# XMC4800 register map
Vendor: Infineon; File version: 1.3.0 (Reference Manual v1.3)
CPU: CM4 r2p0, little endian, MPU, FPU, 6 interrupt priority bits
Registers are 32-bit, read-write, reset 0x0 unless marked. A register's access mark holds for its fields unless they carry their own. Offsets are from the block's base; [hi:lo] are bit positions; {n}, {i} and the like mark numbered series.

## USIC0 — Universal Serial Interface Controller 0
Base 0x40030008
Same registers: USIC1 0x48020008, USIC2 0x48024008
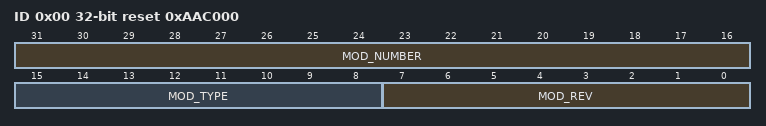
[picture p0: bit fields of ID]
0x00 ID ro reset 0xAAC000 (reset mask 0xFFFFFF00) — Module Identification Register
  [31:16] MOD_NUMBER — Module Number Value
  [15:8] MOD_TYPE — Module Type
  [7:0] MOD_REV — Module Revision Number

## CAN — Controller Area Networks
Base 0x48014000
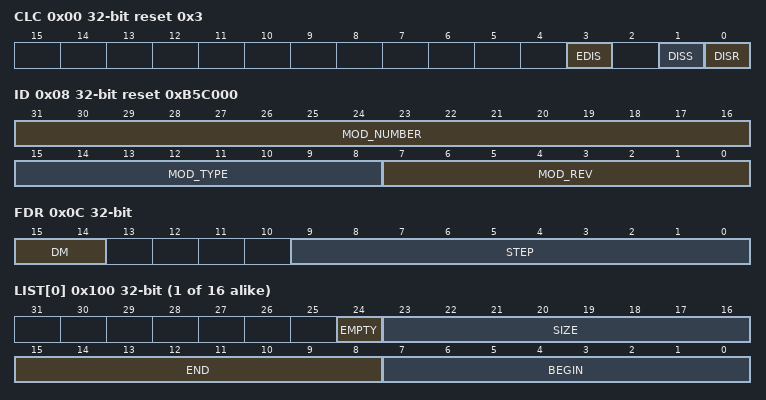
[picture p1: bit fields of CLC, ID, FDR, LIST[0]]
0x00 CLC access per field reset 0x3 — CAN Clock Control Register
  [3] EDIS rw — Sleep Mode Enable Control
  [1] DISS ro — Module Disable Status Bit
  [0] DISR rw — Module Disable Request Bit
0x08 ID ro reset 0xB5C000 (reset mask 0xFFFFFF00) — Module Identification Register
  [31:16] MOD_NUMBER — Module Number Value
  [15:8] MOD_TYPE — Module Type
    192=Define the module as a 32-bit module
  [7:0] MOD_REV — Module Revision Number
0x0C FDR — CAN Fractional Divider Register
  [15:14] DM — Divider Mode
  [9:0] STEP — Step Value
{0x100+4i} LIST[{i}] (i=0..15) ro reset not defined
  [24] EMPTY — List Empty Indication
    0=At least one message object is allocated to list i; 1=No message object is allocated to the list i. List i is empty.
  [23:16] SIZE — List Size
  [15:8] END — List End
  [7:0] BEGIN — List Begin
{0x140+4i} MSPND[{i}] (i=0..7) — Message Pending Register
  [31:0] PND — Message Pending
{0x180+4i} MSID[{i}] (i=0..7) ro reset 0x20 — Message Index Register
  [5:0] INDEX — Message Pending Index
0x1C0 MSIMASK — Message Index Mask Register
  [31:0] IM — Message Index Mask
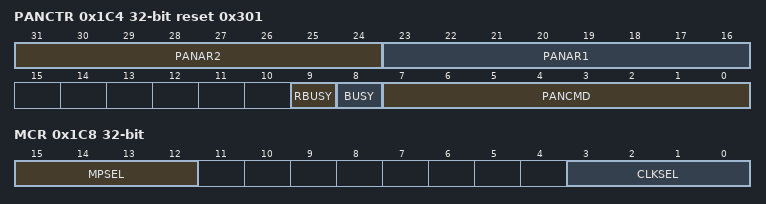
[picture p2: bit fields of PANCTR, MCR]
0x1C4 PANCTR access per field reset 0x301 — Panel Control Register
  [31:24] PANAR2 rw — Panel Argument 2
  [23:16] PANAR1 rw — Panel Argument 1
  [9] RBUSY ro — Result Busy Flag
    0=No update of PANAR1 and PANAR2 is scheduled by the list controller; 1=A list command is running (BUSY = 1) that will write results to PANAR1 and PANAR2, but the results are not yet available
  [8] BUSY ro — Panel Busy Flag
    0=Panel has finished command and is ready to accept a new command; 1=Panel operation is in progress
  [7:0] PANCMD rw — Panel Command
0x1C8 MCR — Module Control Register
  [15:12] MPSEL — Message Pending Selector
  [3:0] CLKSEL — Baud Rate Logic Clock Select
    0=No clock supplied; 1=fPERIPH; 2=fOHP; 4=hard wired to 0; 8=hard wired to 0
0x1CC MITR wo — Module Interrupt Trigger Register
  [7:0] IT — Interrupt Trigger

## DSD — Delta Sigma Demodulator
Base 0x40008000
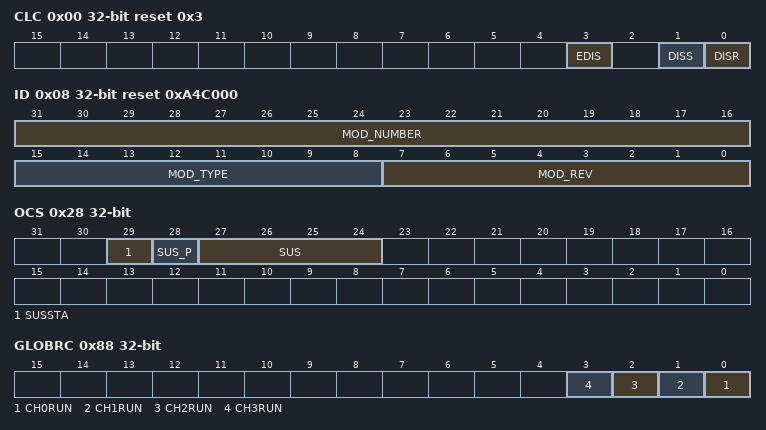
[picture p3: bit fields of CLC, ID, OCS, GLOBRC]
0x00 CLC access per field reset 0x3 — Clock Control Register
  [3] EDIS rw — Sleep Mode Enable Control
    0=Sleep mode request is enabled and functional; 1=Module disregards the sleep mode control signal
  [1] DISS ro — Module Disable Status Bit
    0=Module clock is enabled; 1=Off: module is not clocked
  [0] DISR rw — Module Disable Request Bit
    0=On request: enable the module clock; 1=Off request: stop the module clock
0x08 ID ro reset 0xA4C000 (reset mask 0xFFFFFF00) — Module Identification Register
  [31:16] MOD_NUMBER — Module Number
  [15:8] MOD_TYPE — Module Type
  [7:0] MOD_REV — Module Revision
0x28 OCS access per field — OCDS Control and Status Register
  [29] SUSSTA ro — Suspend State
    0=Module is not (yet) suspended; 1=Module is suspended
  [28] SUS_P wo — SUS Write Protection
  [27:24] SUS rw — OCDS Suspend Control
    0=Will not suspend; 1=Hard suspend: Clock is switched off immediately; 2=Soft suspend channel 0; 3=Soft suspend channel 1; 5=Soft suspend channel 3
0x80 GLOBCFG — Global Configuration Register
  [2:0] MCSEL — Modulator Clock Select
    0=Internal clock off, no source selected; 1=fDSD
0x88 GLOBRC — Global Run Control Register
  [all] fields
    0=Stop channel x; 1=Demodulator channel x is enabled and runs
  [n] CH{n}RUN (n=0..3) — Channel {n} Run Control
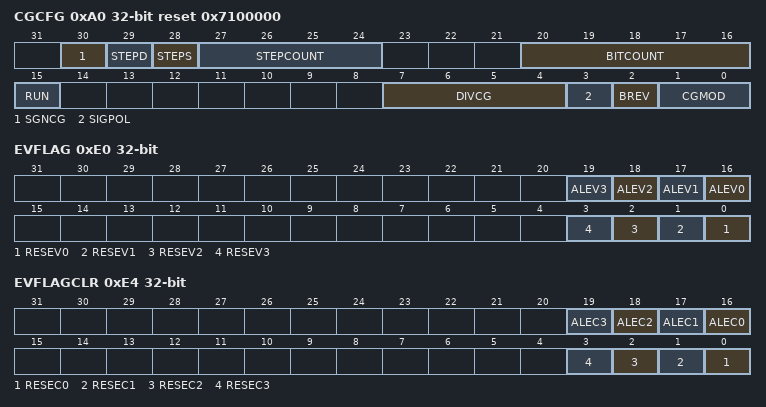
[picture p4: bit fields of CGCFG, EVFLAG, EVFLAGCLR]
0xA0 CGCFG access per field reset 0x7100000 — Carrier Generator Configuration Register
  [30] SGNCG ro — Sign Signal from Carrier Generator
    0=Positive values; 1=Negative values
  [29] STEPD ro — Step Counter Direction
    0=Step counter is counting up; 1=Step counter is counting down
  [28] STEPS ro — Step Counter Sign
    0=Step counter value is positive; 1=Step counter value is negative
  [27:24] STEPCOUNT ro — Step Counter
  [20:16] BITCOUNT ro — Bit Counter
  [15] RUN ro — Run Indicator
    0=Stopped (cleared at the end of a period); 1=Running
  [7:4] DIVCG rw — Divider Factor for the PWM Pattern Signal Generator
    0=fCG = fCLK / 2; 1=fCG = fCLK / 4; 2=fCG = fCLK / 6; 15=fCG = fCLK / 32
  [3] SIGPOL rw — Signal Polarity
    0=Normal: carrier signal begins with +1; 1=Inverted: carrier signal begins with -1
  [2] BREV rw — Bit-Reverse PWM Generation
    0=Normal mode; 1=Bit-reverse mode
  [1:0] CGMOD rw — Carrier Generator Operating Mode
    0=Stopped; 1=Square wave; 2=Triangle; 3=Sine wave
0xE0 EVFLAG — Event Flag Register
  [n+16] ALEV{n} (n=0..3) — Alarm Event
    0=No alarm event; 1=An alarm event has occurred
  [n] RESEV{n} (n=0..3) — Result Event
    0=No result event; 1=A new result has been stored in register RESMx
0xE4 EVFLAGCLR wo — Event Flag Clear Register
  [n+16] ALEC{n} (n=0..3) — Alarm Event Clear
    0=No action; 1=Clear bit ALEVx
  [n] RESEC{n} (n=0..3) — Result Event Clear
    0=No action; 1=Clear bit RESEVx

## Notices in the file
Copyright (c) 2016, Infineon Technologies AG
All rights reserved.
Redistribution and use in source and binary forms, with or without modification,are permitted provided that the
following conditions are met:
Redistributions of source code must retain the above copyright notice, this list of conditions and the following
disclaimer.
Redistributions in binary form must reproduce the above copyright notice, this list of conditions and the following
disclaimer in the documentation and/or other materials provided with the distribution.
Neither the name of the copyright holders nor the names of its contributors may be used to endorse or promote
products derived from this software without specific prior written permission.
THIS SOFTWARE IS PROVIDED BY THE COPYRIGHT HOLDERS AND CONTRIBUTORS "AS IS" AND ANY EXPRESS OR IMPLIED WARRANTIES,
INCLUDING, BUT NOT LIMITED TO, THE IMPLIED WARRANTIES OF MERCHANTABILITY AND FITNESS FOR A PARTICULAR PURPOSE ARE
DISCLAIMED. IN NO EVENT SHALL THE COPYRIGHT HOLDER OR CONTRIBUTORS BE LIABLE  FOR ANY DIRECT, INDIRECT, INCIDENTAL,
SPECIAL, EXEMPLARY, OR CONSEQUENTIAL DAMAGES (INCLUDING, BUT NOT LIMITED TO, PROCUREMENT OF SUBSTITUTE GOODS OR
SERVICES; LOSS OF USE, DATA, OR PROFITS; OR BUSINESS INTERRUPTION) HOWEVER CAUSED AND ON ANY THEORY OF LIABILITY,
WHETHER IN CONTRACT, STRICT LIABILITY,OR TORT (INCLUDING NEGLIGENCE OR OTHERWISE) ARISING IN ANY WAY OUT OF THE USE
OF THIS SOFTWARE, EVEN IF ADVISED OF THE POSSIBILITY OF SUCH DAMAGE.
